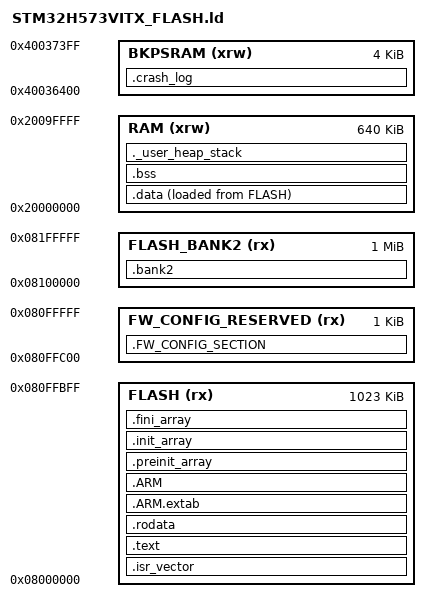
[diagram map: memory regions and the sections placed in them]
/*
******************************************************************************
**
** @file        : LinkerScript.ld
**
** @author      : Auto-generated by STM32CubeIDE
**
** @brief       : Linker script for STM32H573VITx Device from STM32H5 series
**                      2048KBytes FLASH
**                      640KBytes RAM
**
**                Set heap size, stack size and stack location according
**                to application requirements.
**
**                Set memory bank area and size if external memory is used
**
**  Target      : STMicroelectronics STM32
**
**  Distribution: The file is distributed as is, without any warranty
**                of any kind.
**
******************************************************************************
** @attention
**
** Copyright (c) 2024 STMicroelectronics.
** All rights reserved.
**
** This software is licensed under terms that can be found in the LICENSE file
** in the root directory of this software component.
** If no LICENSE file comes with this software, it is provided AS-IS.
**
******************************************************************************
*/

/* Entry Point */
ENTRY(Reset_Handler)

/* Highest address of the user mode stack */
_estack = ORIGIN(RAM) + LENGTH(RAM); /* end of "RAM" Ram type memory */

_Min_Heap_Size = 0x400; /* required amount of heap */
_Min_Stack_Size = 0x400; /* required amount of stack */

/* Memories definition
 *
 * STM32H573VIT6 has 2MB dual-bank flash:
 *   Bank 1: 0x08000000 - 0x080FFFFF (1024K, last 1K reserved for FW config)
 *   Bank 2: 0x08100000 - 0x081FFFFF (1024K, available for code growth or A/B OTA)
 *
 * BKPSRAM (4K at 0x40036400) is exposed for crash telemetry that survives reset.
 */
MEMORY
{
  RAM         (xrw)   : ORIGIN = 0x20000000,   LENGTH = 640K
  FLASH       (rx)    : ORIGIN = 0x08000000,   LENGTH = 1023K
  FW_CONFIG_RESERVED  (rx) : ORIGIN = 0x080FFC00, LENGTH = 1K
  FLASH_BANK2 (rx)    : ORIGIN = 0x08100000,   LENGTH = 1024K
  BKPSRAM     (xrw)   : ORIGIN = 0x40036400,   LENGTH = 4K
}

/* Sections */
SECTIONS
{
  /* The startup code into "FLASH" Rom type memory */
  .isr_vector :
  {
    . = ALIGN(4);
    KEEP(*(.isr_vector)) /* Startup code */
    . = ALIGN(4);
  } >FLASH
  
  .FW_CONFIG_SECTION :
  {
  	. = ALIGN(4);
  	__FW_CONFIG_SECTION_start__ = .;  
  	KEEP(*(.FW_CONFIG_SECTION))
  	KEEP(*(.text.add))
  	__FW_CONFIG_SECTION_end__ = .;  	
  } >FW_CONFIG_RESERVED  

  /* The program code and other data into "FLASH" Rom type memory */
  .text :
  {
    . = ALIGN(4);
    *(.text)           /* .text sections (code) */
    *(.text*)          /* .text* sections (code) */
    *(.glue_7)         /* glue arm to thumb code */
    *(.glue_7t)        /* glue thumb to arm code */
    *(.eh_frame)

    KEEP (*(.init))
    KEEP (*(.fini))

    . = ALIGN(4);
    _etext = .;        /* define a global symbols at end of code */
  } >FLASH
  
  ASSERT(LENGTH(FW_CONFIG_RESERVED) >= (__FW_CONFIG_SECTION_end__ - __FW_CONFIG_SECTION_start__), "FW_CONFIG_RESERVED overflowed!")

  /* Constant data into "FLASH" Rom type memory */
  .rodata :
  {
    . = ALIGN(4);
    *(.rodata)         /* .rodata sections (constants, strings, etc.) */
    *(.rodata*)        /* .rodata* sections (constants, strings, etc.) */
    . = ALIGN(4);
  } >FLASH

  .ARM.extab (READONLY) : /* The "READONLY" keyword is only supported in GCC11 and later, remove it if using GCC10 or earlier. */
  {
    . = ALIGN(4);
    *(.ARM.extab* .gnu.linkonce.armextab.*)
    . = ALIGN(4);
  } >FLASH

  .ARM (READONLY) : /* The "READONLY" keyword is only supported in GCC11 and later, remove it if using GCC10 or earlier. */
  {
    . = ALIGN(4);
    __exidx_start = .;
    *(.ARM.exidx*)
    __exidx_end = .;
    . = ALIGN(4);
  } >FLASH

  .preinit_array (READONLY) : /* The "READONLY" keyword is only supported in GCC11 and later, remove it if using GCC10 or earlier. */
  {
    . = ALIGN(4);
    PROVIDE_HIDDEN (__preinit_array_start = .);
    KEEP (*(.preinit_array*))
    PROVIDE_HIDDEN (__preinit_array_end = .);
    . = ALIGN(4);
  } >FLASH

  .init_array (READONLY) : /* The "READONLY" keyword is only supported in GCC11 and later, remove it if using GCC10 or earlier. */
  {
    . = ALIGN(4);
    PROVIDE_HIDDEN (__init_array_start = .);
    KEEP (*(SORT(.init_array.*)))
    KEEP (*(.init_array*))
    PROVIDE_HIDDEN (__init_array_end = .);
    . = ALIGN(4);
  } >FLASH

  .fini_array (READONLY) : /* The "READONLY" keyword is only supported in GCC11 and later, remove it if using GCC10 or earlier. */
  {
    . = ALIGN(4);
    PROVIDE_HIDDEN (__fini_array_start = .);
    KEEP (*(SORT(.fini_array.*)))
    KEEP (*(.fini_array*))
    PROVIDE_HIDDEN (__fini_array_end = .);
    . = ALIGN(4);
  } >FLASH

  /* Used by the startup to initialize data */
  _sidata = LOADADDR(.data);

  /* Initialized data sections into "RAM" Ram type memory */
  .data :
  {
    . = ALIGN(4);
    _sdata = .;        /* create a global symbol at data start */
    *(.data)           /* .data sections */
    *(.data*)          /* .data* sections */
    *(.RamFunc)        /* .RamFunc sections */
    *(.RamFunc*)       /* .RamFunc* sections */

    . = ALIGN(4);
    _edata = .;        /* define a global symbol at data end */

  } >RAM AT> FLASH

  /* Uninitialized data section into "RAM" Ram type memory */
  . = ALIGN(4);
  .bss :
  {
    /* This is used by the startup in order to initialize the .bss section */
    _sbss = .;         /* define a global symbol at bss start */
    __bss_start__ = _sbss;
    *(.bss)
    *(.bss*)
    *(COMMON)

    . = ALIGN(4);
    _ebss = .;         /* define a global symbol at bss end */
    __bss_end__ = _ebss;
  } >RAM

  /* User_heap_stack section, used to check that there is enough "RAM" Ram  type memory left */
  ._user_heap_stack :
  {
    . = ALIGN(8);
    PROVIDE ( end = . );
    PROVIDE ( _end = . );
    . = . + _Min_Heap_Size;
    . = . + _Min_Stack_Size;
    . = ALIGN(8);
  } >RAM

  /* Crash telemetry — survives reset via backup SRAM. Populated by HardFault
   * and friends (CFSR/HFSR/MMFAR/BFAR + stacked frame + task name), consumed
   * by main on next boot. NOLOAD: no init image; its contents are preserved
   * across software-reset and warm boots. */
  .crash_log (NOLOAD) :
  {
    . = ALIGN(4);
    *(.crash_log)
    . = ALIGN(4);
  } >BKPSRAM

  /* Bank 2 of the dual-bank flash. Empty by default. Targets that need to be
   * placed in bank 2 should declare a section like .text.bank2 and assign it
   * here explicitly. Reserved for code growth and future A/B firmware update. */
  .bank2 (NOLOAD) :
  {
    *(.text.bank2)
    *(.rodata.bank2)
  } >FLASH_BANK2

  /* Remove information from the compiler libraries */
  /DISCARD/ :
  {
    libc.a ( * )
    libm.a ( * )
    libgcc.a ( * )
  }

  .ARM.attributes 0 : { *(.ARM.attributes) }
}
